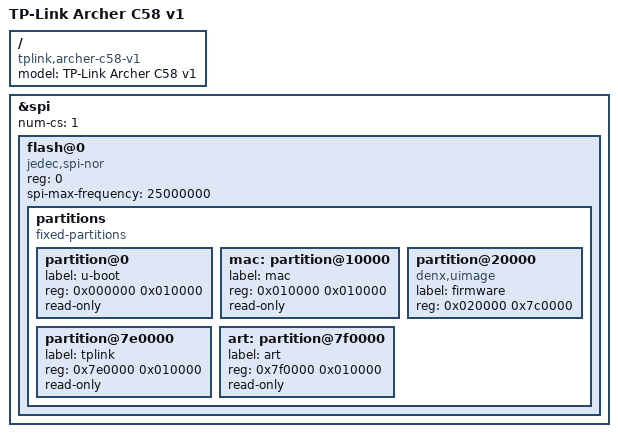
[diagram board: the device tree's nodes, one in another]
// SPDX-License-Identifier: GPL-2.0-or-later OR MIT
/dts-v1/;

#include "qca9561_tplink_archer-c5x.dtsi"

/ {
	compatible = "tplink,archer-c58-v1", "qca,qca9560";
	model = "TP-Link Archer C58 v1";
};

&spi {
	status = "okay";
	num-cs = <1>;

	flash@0 {
		compatible = "jedec,spi-nor";
		reg = <0>;
		spi-max-frequency = <25000000>;

		partitions {
			compatible = "fixed-partitions";
			#address-cells = <1>;
			#size-cells = <1>;

			partition@0 {
				label = "u-boot";
				reg = <0x000000 0x010000>;
				read-only;
			};

			mac: partition@10000 {
				label = "mac";
				reg = <0x010000 0x010000>;
				read-only;
			};

			partition@20000 {
				compatible = "denx,uimage";
				label = "firmware";
				reg = <0x020000 0x7c0000>;
			};

			partition@7e0000 {
				label = "tplink";
				reg = <0x7e0000 0x010000>;
				read-only;
			};

			art: partition@7f0000 {
				label = "art";
				reg = <0x7f0000 0x010000>;
				read-only;
			};
		};
	};
};
